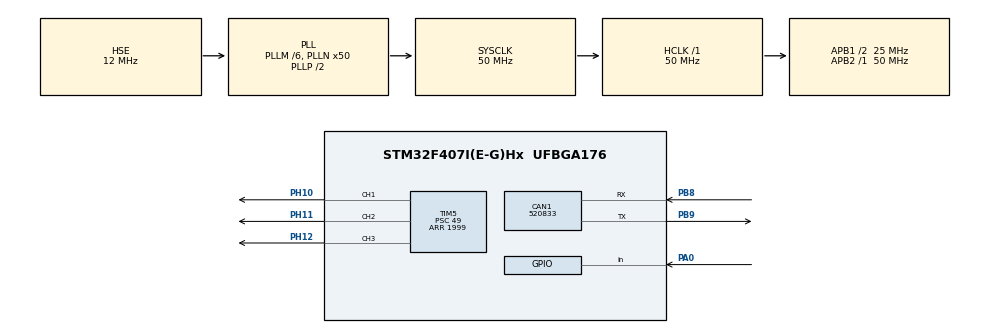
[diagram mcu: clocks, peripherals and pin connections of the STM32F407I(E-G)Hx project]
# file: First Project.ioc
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CAN1.CalculateBaudRate=520833
CAN1.CalculateTimeBit=1920
CAN1.CalculateTimeQuantum=640.0
Mcu.Family=STM32F4
Mcu.Name=STM32F407I(E-G)Hx
Mcu.Package=UFBGA176
NVIC.PriorityGroup=NVIC_PRIORITYGROUP_4
PA0-WKUP.Signal=GPIO_Input
PB8.Mode=CAN_Activate
PB8.Signal=CAN1_RX
PB9.Mode=CAN_Activate
PB9.Signal=CAN1_TX
PH0-OSC_IN.Mode=HSE-External-Oscillator
PH0-OSC_IN.Signal=RCC_OSC_IN
PH1-OSC_OUT.Mode=HSE-External-Oscillator
PH1-OSC_OUT.Signal=RCC_OSC_OUT
PH10.Signal=S_TIM5_CH1
PH11.Signal=S_TIM5_CH2
PH12.Signal=S_TIM5_CH3
ProjectManager.HeapSize=0x200
ProjectManager.StackSize=0x400
ProjectManager.TargetToolchain=STM32CubeIDE
RCC.48MHZClocksFreq_Value=25000000
RCC.AHBFreq_Value=50000000
RCC.APB1CLKDivider=RCC_HCLK_DIV2
RCC.APB1Freq_Value=25000000
RCC.APB1TimFreq_Value=50000000
RCC.APB2Freq_Value=50000000
RCC.APB2TimFreq_Value=50000000
RCC.CortexFreq_Value=50000000
RCC.HCLKFreq_Value=50000000
RCC.HSE_VALUE=12000000
RCC.HSI_VALUE=16000000
RCC.LSE_VALUE=32768
RCC.PLLM=6
RCC.PLLN=50
RCC.PLLSourceVirtual=RCC_PLLSOURCE_HSE
RCC.SYSCLKFreq_VALUE=50000000
RCC.SYSCLKSource=RCC_SYSCLKSOURCE_PLLCLK
RCC.VCOOutputFreq_Value=100000000
SH.S_TIM5_CH1.0=TIM5_CH1,PWM Generation1 CH1
SH.S_TIM5_CH2.0=TIM5_CH2,PWM Generation2 CH2
SH.S_TIM5_CH3.0=TIM5_CH3,PWM Generation3 CH3
TIM5.Channel-PWM\ Generation1\ CH1=TIM_CHANNEL_1
TIM5.Channel-PWM\ Generation2\ CH2=TIM_CHANNEL_2
TIM5.Channel-PWM\ Generation3\ CH3=TIM_CHANNEL_3
TIM5.Period=1999
TIM5.Prescaler=49
board=custom

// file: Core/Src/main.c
/* USER CODE BEGIN Header */
/**
  ******************************************************************************
  * @file           : main.c
  * @brief          : Main program body
  ******************************************************************************
  * @attention
  *
  * Copyright (c) 2024 STMicroelectronics.
  * All rights reserved.
  *
  * This software is licensed under terms that can be found in the LICENSE file
  * in the root directory of this software component.
  * If no LICENSE file comes with this software, it is provided AS-IS.
  *
  ******************************************************************************
  */
/* USER CODE END Header */
#include "main.h"

CAN_HandleTypeDef hcan1;

TIM_HandleTypeDef htim5;

void SystemClock_Config(void);
static void MX_GPIO_Init(void);
static void MX_CAN1_Init(void);
static void MX_TIM5_Init(void);

int main(void)
{

  /* MCU Configuration--------------------------------------------------------*/

  /* Reset of all peripherals, Initializes the Flash interface and the Systick. */
  HAL_Init();

  /* Configure the system clock */
  SystemClock_Config();

  /* Initialize all configured peripherals */
  MX_GPIO_Init();
  MX_CAN1_Init();
  MX_TIM5_Init();
  /* USER CODE BEGIN 2 */
  HAL_TIM_Base_Start(&htim5);
  HAL_TIM_PWM_Start(&htim5, TIM_CHANNEL_1);
  HAL_TIM_PWM_Start(&htim5, TIM_CHANNEL_2);
  HAL_TIM_PWM_Start(&htim5, TIM_CHANNEL_3);
  /* USER CODE END 2 */

  /* Infinite loop */
  while (1)
  {

    /* USER CODE BEGIN 3 */
	for (int i = 0; i < 1999; i++) {
		__HAL_TIM_SET_COMPARE(&htim5, TIM_CHANNEL_1, i);
		__HAL_TIM_SET_COMPARE(&htim5, TIM_CHANNEL_2, i);
		__HAL_TIM_SET_COMPARE(&htim5, TIM_CHANNEL_3, i);
		HAL_Delay(1);
	}

  }
  /* USER CODE END 3 */
}

void SystemClock_Config(void)
{
  RCC_OscInitTypeDef RCC_OscInitStruct = {0};
  RCC_ClkInitTypeDef RCC_ClkInitStruct = {0};

  /** Configure the main internal regulator output voltage
  */
  __HAL_RCC_PWR_CLK_ENABLE();
  __HAL_PWR_VOLTAGESCALING_CONFIG(PWR_REGULATOR_VOLTAGE_SCALE1);

  /** Initializes the RCC Oscillators according to the specified parameters
  * in the RCC_OscInitTypeDef structure.
  */
  RCC_OscInitStruct.OscillatorType = RCC_OSCILLATORTYPE_HSE;
  RCC_OscInitStruct.HSEState = RCC_HSE_ON;
  RCC_OscInitStruct.PLL.PLLState = RCC_PLL_ON;
  RCC_OscInitStruct.PLL.PLLSource = RCC_PLLSOURCE_HSE;
  RCC_OscInitStruct.PLL.PLLM = 6;
  RCC_OscInitStruct.PLL.PLLN = 50;
  RCC_OscInitStruct.PLL.PLLP = RCC_PLLP_DIV2;
  RCC_OscInitStruct.PLL.PLLQ = 4;
  if (HAL_RCC_OscConfig(&RCC_OscInitStruct) != HAL_OK)
  {
    Error_Handler();
  }

  /** Initializes the CPU, AHB and APB buses clocks
  */
  RCC_ClkInitStruct.ClockType = RCC_CLOCKTYPE_HCLK|RCC_CLOCKTYPE_SYSCLK
                              |RCC_CLOCKTYPE_PCLK1|RCC_CLOCKTYPE_PCLK2;
  RCC_ClkInitStruct.SYSCLKSource = RCC_SYSCLKSOURCE_PLLCLK;
  RCC_ClkInitStruct.AHBCLKDivider = RCC_SYSCLK_DIV1;
  RCC_ClkInitStruct.APB1CLKDivider = RCC_HCLK_DIV2;
  RCC_ClkInitStruct.APB2CLKDivider = RCC_HCLK_DIV1;

  if (HAL_RCC_ClockConfig(&RCC_ClkInitStruct, FLASH_LATENCY_1) != HAL_OK)
  {
    Error_Handler();
  }
}

static void MX_CAN1_Init(void)
{

  hcan1.Instance = CAN1;
  hcan1.Init.Prescaler = 16;
  hcan1.Init.Mode = CAN_MODE_NORMAL;
  hcan1.Init.SyncJumpWidth = CAN_SJW_1TQ;
  hcan1.Init.TimeSeg1 = CAN_BS1_1TQ;
  hcan1.Init.TimeSeg2 = CAN_BS2_1TQ;
  hcan1.Init.TimeTriggeredMode = DISABLE;
  hcan1.Init.AutoBusOff = DISABLE;
  hcan1.Init.AutoWakeUp = DISABLE;
  hcan1.Init.AutoRetransmission = DISABLE;
  hcan1.Init.ReceiveFifoLocked = DISABLE;
  hcan1.Init.TransmitFifoPriority = DISABLE;
  if (HAL_CAN_Init(&hcan1) != HAL_OK)
  {
    Error_Handler();
  }

}

static void MX_TIM5_Init(void)
{

  TIM_MasterConfigTypeDef sMasterConfig = {0};
  TIM_OC_InitTypeDef sConfigOC = {0};

  htim5.Instance = TIM5;
  htim5.Init.Prescaler = 49;
  htim5.Init.CounterMode = TIM_COUNTERMODE_UP;
  htim5.Init.Period = 1999;
  htim5.Init.ClockDivision = TIM_CLOCKDIVISION_DIV1;
  htim5.Init.AutoReloadPreload = TIM_AUTORELOAD_PRELOAD_DISABLE;
  if (HAL_TIM_PWM_Init(&htim5) != HAL_OK)
  {
    Error_Handler();
  }
  sMasterConfig.MasterOutputTrigger = TIM_TRGO_RESET;
  sMasterConfig.MasterSlaveMode = TIM_MASTERSLAVEMODE_DISABLE;
  if (HAL_TIMEx_MasterConfigSynchronization(&htim5, &sMasterConfig) != HAL_OK)
  {
    Error_Handler();
  }
  sConfigOC.OCMode = TIM_OCMODE_PWM1;
  sConfigOC.Pulse = 0;
  sConfigOC.OCPolarity = TIM_OCPOLARITY_HIGH;
  sConfigOC.OCFastMode = TIM_OCFAST_DISABLE;
  if (HAL_TIM_PWM_ConfigChannel(&htim5, &sConfigOC, TIM_CHANNEL_1) != HAL_OK)
  {
    Error_Handler();
  }
  if (HAL_TIM_PWM_ConfigChannel(&htim5, &sConfigOC, TIM_CHANNEL_2) != HAL_OK)
  {
    Error_Handler();
  }
  if (HAL_TIM_PWM_ConfigChannel(&htim5, &sConfigOC, TIM_CHANNEL_3) != HAL_OK)
  {
    Error_Handler();
  }
  HAL_TIM_MspPostInit(&htim5);

}

static void MX_GPIO_Init(void)
{
  GPIO_InitTypeDef GPIO_InitStruct = {0};

  /* GPIO Ports Clock Enable */
  __HAL_RCC_GPIOB_CLK_ENABLE();
  __HAL_RCC_GPIOH_CLK_ENABLE();
  __HAL_RCC_GPIOA_CLK_ENABLE();

  /*Configure GPIO pin : PA0 */
  GPIO_InitStruct.Pin = GPIO_PIN_0;
  GPIO_InitStruct.Mode = GPIO_MODE_INPUT;
  GPIO_InitStruct.Pull = GPIO_NOPULL;
  HAL_GPIO_Init(GPIOA, &GPIO_InitStruct);

}

void Error_Handler(void)
{
  __disable_irq();
  while (1)
  {
  }
}
